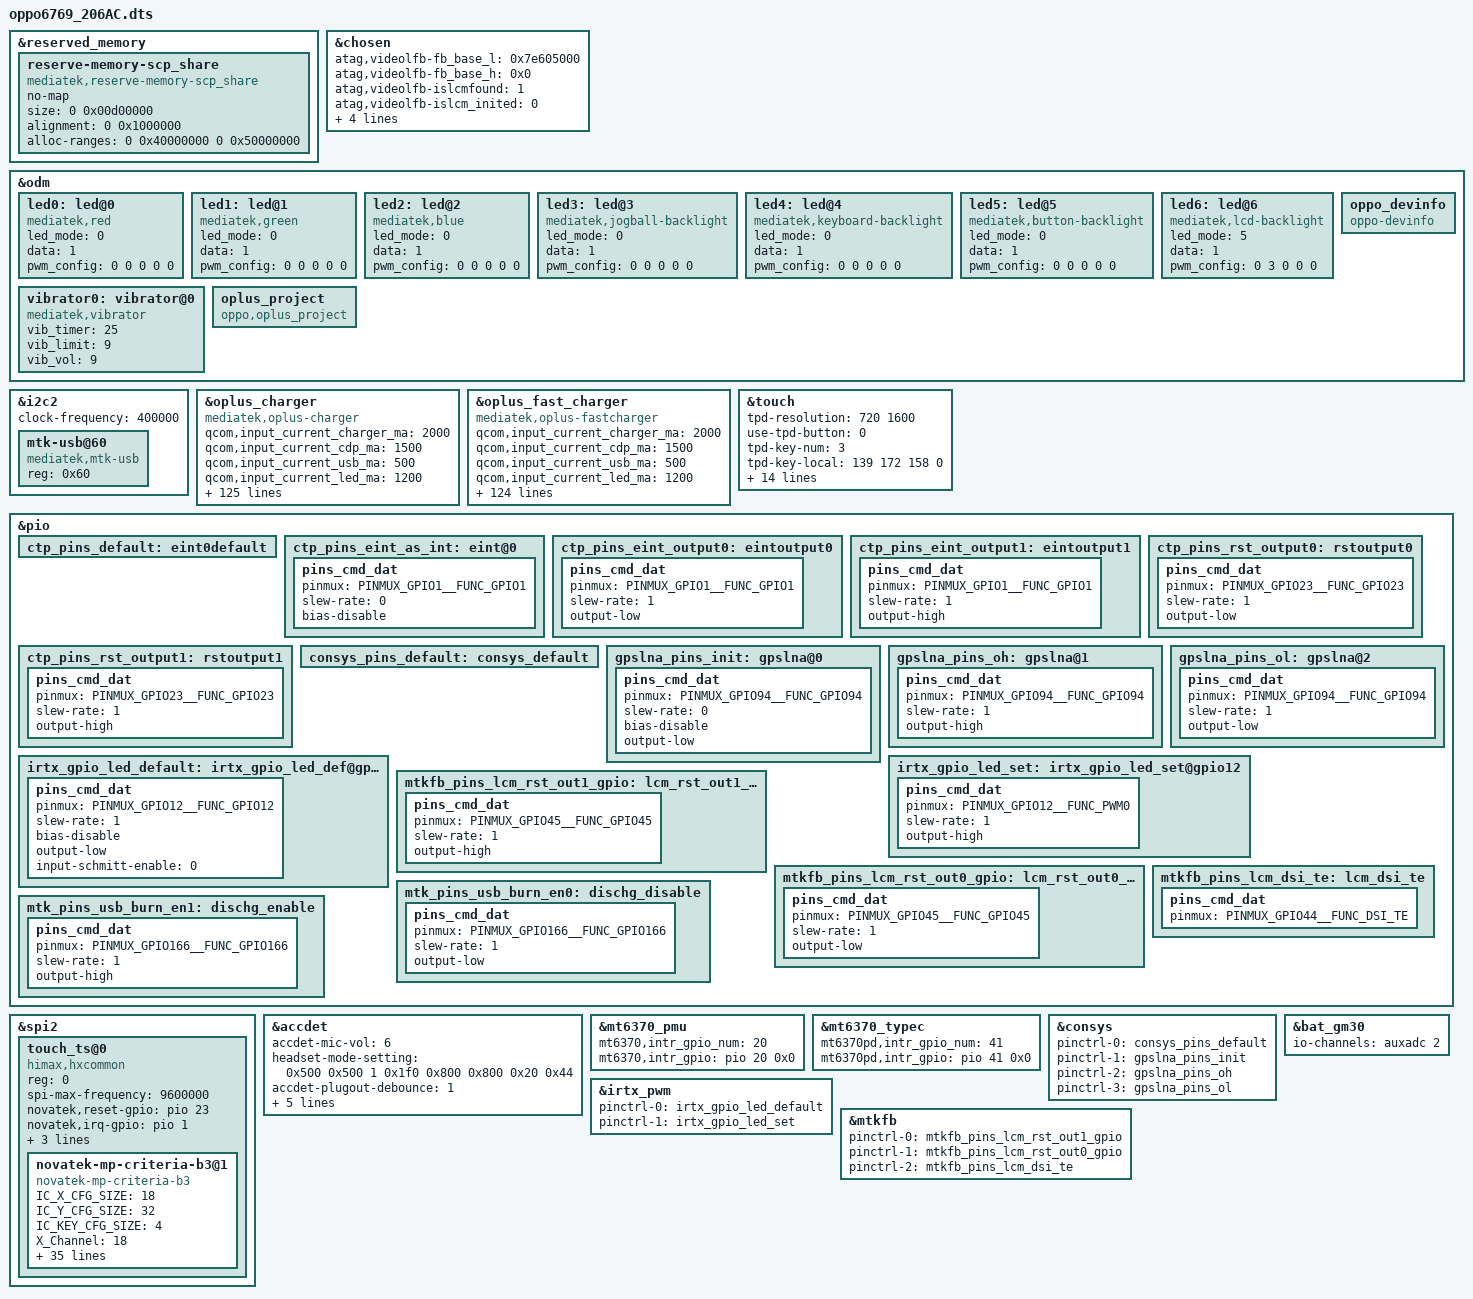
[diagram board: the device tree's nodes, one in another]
/*
 * Copyright (C) 2019 MediaTek Inc.
 *
 * This program is free software; you can redistribute it and/or modify
 * it under the terms of the GNU General Public License version 2 as
 * published by the Free Software Foundation.
 *
 * This program is distributed in the hope that it will be useful,
 * but WITHOUT ANY WARRANTY; without even the implied warranty of
 * MERCHANTABILITY or FITNESS FOR A PARTICULAR PURPOSE.
 * See http://www.gnu.org/licenses/gpl-2.0.html for more details.
 */

/dts-v1/;
/plugin/;
#include <dt-bindings/interrupt-controller/irq.h>
#include <dt-bindings/interrupt-controller/arm-gic.h>
#include <dt-bindings/pinctrl/mt6768-pinfunc.h>

&reserved_memory {
	reserve-memory-scp_share {
		compatible = "mediatek,reserve-memory-scp_share";
		no-map;
		size = <0 0x00d00000>;
		alignment = <0 0x1000000>;
		alloc-ranges = <0 0x40000000 0 0x50000000>;
	};
};

/* chosen */
&chosen {

	atag,videolfb-fb_base_l = <0x7e605000>;
	atag,videolfb-fb_base_h = <0x0>;
	atag,videolfb-islcmfound = <1>;
	atag,videolfb-islcm_inited = <0>;
	atag,videolfb-fps= <6000>;
	atag,videolfb-vramSize= <0x017e8000>;
	atag,videolfb-lcmname=
		"hx83112b_fhdp_dsi_cmd_auo_rt5081_drv";
};

&odm {
	led0:led@0 {
		compatible = "mediatek,red";
		led_mode = <0>;
		data = <1>;
		pwm_config = <0 0 0 0 0>;
	};
	led1:led@1 {
		compatible = "mediatek,green";
		led_mode = <0>;
		data = <1>;
		pwm_config = <0 0 0 0 0>;
	};
	led2:led@2 {
		compatible = "mediatek,blue";
		led_mode = <0>;
		data = <1>;
		pwm_config = <0 0 0 0 0>;
	};
	led3:led@3 {
		compatible = "mediatek,jogball-backlight";
		led_mode = <0>;
		data = <1>;
		pwm_config = <0 0 0 0 0>;
	};
	led4:led@4 {
		compatible = "mediatek,keyboard-backlight";
		led_mode = <0>;
		data = <1>;
		pwm_config = <0 0 0 0 0>;
	};
	led5:led@5 {
		compatible = "mediatek,button-backlight";
		led_mode = <0>;
		data = <1>;
		pwm_config = <0 0 0 0 0>;
	};
	led6:led@6 {
		compatible = "mediatek,lcd-backlight";
		led_mode = <5>;
		data = <1>;
		pwm_config = <0 3 0 0 0>;
	};
	vibrator0:vibrator@0 {
		compatible = "mediatek,vibrator";
		vib_timer = <25>;
		vib_limit = <9>;
		vib_vol= <9>;
	};
/*VNDOR_EDIT oppo project start */
	oplus_project:oplus_project {
		compatible = "oppo,oplus_project";
	};
	oppo_devinfo:oppo_devinfo {
		compatible = "oppo-devinfo";
	};
};

&i2c2 {
	clock-frequency = <400000>;

	mtk-usb@60 {
		compatible = "mediatek,mtk-usb";
		reg = <0x60>;
		status = "okay";
	};
};

//#ifdef ODM_WT_EDIT
&oplus_charger {
	compatible = "mediatek,oplus-charger";
	//pinctrl-names = "default", "charger_gpio_as_output_low", "charger_gpio_as_output_high", "ship_sleep", "ship_active", "shortc_active";
	//pinctrl-0 = <&charger_pins_default>;
	//pinctrl-1 = <&charger_pins_eint_output0>;
	//pinctrl-2 = <&charger_pins_eint_output1>;
	//pinctrl-3 = <&ship_sleep_gpio>;
	//pinctrl-4 = <&ship_active_gpio>;
	//pinctrl-5 = <&shortc_active_gpio>;

	//for oplus chg framework:
	qcom,input_current_charger_ma = <2000>;
	qcom,input_current_cdp_ma = <1500>;
	qcom,input_current_usb_ma = <500>;
	qcom,input_current_led_ma = <1200>;
	qcom,input_current_led_ma_forcmcc = <500>;
	qcom,input_current_camera_ma = <1200>;
	qcom,input_current_calling_ma = <1200>;
	
	qcom,input_current_led_ma_high = <1200>;
	qcom,input_current_led_ma_warm = <1500>;
	qcom,input_current_led_ma_normal = <2000>;

	qcom,led_high_bat_decidegc = <370>;
	qcom,led_warm_bat_decidegc = <350>;

	qcom,iterm_disabled = <0>;
	qcom,iterm_ma = <265>;
	qcom,recharge-mv = <115>;

	qcom,batt_capacity_mah = <5000>; /*typical capacity*/
	//qcom,batt_capacity_mah = <3900>; /*rated capacity*/

	qcom,removed_bat_decidegc = <190>;  /* < -19C */

	qcom,cold_bat_decidegc = <20>;  /* -2C ~ 0C */
	qcom,temp_cold_vfloat_mv = <3980>;
	qcom,temp_cold_fastchg_current_ma = <350>;

	qcom,little_cold_bat_decidegc = <0>;	/* 0C ~ 5C */
	qcom,temp_little_cold_vfloat_mv = <4435>;
	qcom,temp_little_cold_fastchg_current_ma_high = <650>;
	qcom,temp_little_cold_fastchg_current_ma_low = <650>;
	qcom,temp_little_cold_fastchg_current_ma = <650>;
	monet,temp_little_cold_usbchg_current_ma_high = <650>;
	monet,temp_little_cold_usbchg_current_ma_low = <650>;
	monet,temp_little_cold_usbchg_current_ma = <650>;

	qcom,cool_bat_decidegc = <50>;	/* 5C ~ 12C */
	qcom,temp_cool_vfloat_mv = <4435>;
	qcom,temp_cool_fastchg_current_ma_high = <1350>;
	qcom,temp_cool_fastchg_current_ma_low = <650>;
	monet,temp_cool_usbchg_current_ma_high = <650>;
	monet,temp_cool_usbchg_current_ma_low = <550>;

	qcom,little_cool_bat_decidegc = <120>;	/* 12C ~ 16C */
	qcom,temp_little_cool_vfloat_mv = <4435>;
	qcom,temp_little_cool_fastchg_current_ma = <2050>;
	monet,temp_little_cool_usbchg_current_ma = <550>;

	qcom,normal_bat_decidegc = <160>;	/* 16C ~ 45C */
	qcom,temp_normal_fastchg_current_ma = <2200>;
	monet,temp_normal_usbchg_current_ma = <550>;
	qcom,temp_normal_vfloat_mv = <4435>;

	qcom,warm_bat_decidegc = <440>;		/* 44C ~ 53C */ /*8pin Bat Vooc project need add 3 degree C*/
	qcom,temp_warm_vfloat_mv = <4130>;
	qcom,temp_warm_fastchg_current_ma = <1350>;
	monet,temp_warm_usbchg_current_ma = <550>;
	qcom,temp_warm_fastchg_current_ma_led_on = <500>;

	qcom,hot_bat_decidegc = <530>;  /* > 53C */

	qcom,non_standard_vfloat_mv = <3980>;
	qcom,non_standard_fastchg_current_ma = <512>;

	qcom,short_c_bat_cv_mv = <4330>;
	qcom,short_c_bat_vfloat_mv = <3800>;
	qcom,short_c_bat_fastchg_current_ma = <512>;
	qcom,short_c_bat_vfloat_sw_limit = <3750>;

	qcom,cold_vfloat_sw_limit = <3930>;
	qcom,little_cold_vfloat_sw_limit = <4380>;
	qcom,cool_vfloat_sw_limit = <4380>;
	qcom,little_cool_vfloat_sw_limit = <4380>;
	qcom,normal_vfloat_sw_limit = <4380>;
	qcom,warm_vfloat_sw_limit = <4080>;
	qcom,non_standard_vfloat_sw_limit = <3930>;

	qcom,max_chg_time_sec = <36000>;
	qcom,charger_hv_thr = <5800>;
	qcom,charger_recv_thr = <5800>;
	qcom,charger_lv_thr = <3400>;
	qcom,vbatt_full_thr = <4400>;
	qcom,vbatt_hv_thr = <4550>;

	qcom,vfloat_step_mv = <10>;
	qcom,non_standard_vfloat_over_sw_limit = <4000>;
	qcom,cold_vfloat_over_sw_limit = <4000>;
	qcom,little_cold_vfloat_over_sw_limit = <4450>;
	qcom,cool_vfloat_over_sw_limit = <4450>;
	qcom,little_cool_vfloat_over_sw_limit = <4450>;
	qcom,normal_vfloat_over_sw_limit = <4450>;
	qcom,warm_vfloat_over_sw_limit = <4150>;

	qcom,vbatt_power_off = <3300>;
	qcom,vbatt_soc_1 = <3410>;
	qcom,vooc_project = <0>;
	qcom,vbatt_num = <1>;

	qcom,normal_vterm_hw_inc = <150>;
	qcom,non_normal_vterm_hw_inc = <10>;

	qcom,ff1_normal_fastchg_ma = <1088>;
	qcom,ffc2_normal_fastchg_ma = <780>;/*16C~35c*/
	qcom,ffc2_temp_warm_decidegc = <350>;
	qcom,ffc2_warm_fastchg_ma = <840>;/*35C~40c*/
	qcom,ffc2_temp_high_decidegc = <400>;
	qcom,ffc2_temp_low_decidegc = <120>;
	qcom,ff1_exit_step_ma = <488>;
	qcom,ff1_warm_exit_step_ma = <418>;
	qcom,ffc2_exit_step_ma = <180>;
	qcom,ffc2_warm_exit_step_ma = <170>;

	qcom,ffc_normal_vfloat_sw_limit = <4430>;
	qcom,ffc_temp_normal_vfloat_mv = <4500>;
	qcom,ffc_normal_vfloat_over_sw_limit = <4500>;

	qcom,default_iterm_ma = <265>;
	qcom,default_temp_normal_fastchg_current_ma = <2200>;
	qcom,default_normal_vfloat_sw_limit = <4380>;
	qcom,default_temp_normal_vfloat_mv = <4435>;
	qcom,default_normal_vfloat_over_sw_limit = <4450>;

	//for 2nd chip:
	qcom,iterm_ma_2nd = <300>;
	qcom,recharge-mv_2nd = <121>;

	qcom,temp_little_cold_vfloat_mv_2nd = <4391>;	/* 0C ~ 5C */
	qcom,temp_cool_vfloat_mv_2nd = <4391>;	/* 5C ~ 12C */
	qcom,temp_little_cool_vfloat_mv_2nd = <4391>;	/* 12C ~ 16C */
	qcom,temp_normal_vfloat_mv_2nd = <4391>;	/* 16C ~ 45C */

	qcom,little_cold_vfloat_over_sw_limit_2nd = <4395>;
	qcom,cool_vfloat_over_sw_limit_2nd = <4395>;
	qcom,little_cool_vfloat_over_sw_limit_2nd = <4395>;
	qcom,normal_vfloat_over_sw_limit_2nd = <4395>;

	qcom,default_iterm_ma_2nd = <300>;
	qcom,default_temp_normal_vfloat_mv_2nd = <4391>;
	qcom,default_normal_vfloat_over_sw_limit_2nd = <4395>;

	//for control:
	//qcom,suspend_after_full;
	qcom,check_batt_full_by_sw;
	//qcom,external_gauge;
	qcom,chg_ctrl_by_calling;
	qcom,chg_ctrl_by_lcd;
	qcom,chg_ctrl_by_camera;
	qcom,sw_vfloat_over_protect_enable;
	//qcom,ffc_support;

	//GPIO config:
	//qcom,chargerid_switch-gpio = <&pio 97 0x00>;
	//qcom,ship-gpio = <&pio 155 0x00>;
	//qcom,shortc-gpio = <&pio 77 0x00>;

	io-channels = <&auxadc 3>, <&auxadc 4>;
	io-channel-names = "usbtemp-ch3", "usbtemp-ch4";

	qcom,dischg-gpio = <&pio 166 0x00>;
	pinctrl-names = "dischg_disable", "dischg_enable";
	pinctrl-0 = <&mtk_pins_usb_burn_en0>;
	pinctrl-1 = <&mtk_pins_usb_burn_en1>;
	status = "okay";
};

&oplus_fast_charger {
	compatible = "mediatek,oplus-fastcharger";
	//pinctrl-names = "default", "charger_gpio_as_output_low", "charger_gpio_as_output_high", "ship_sleep", "ship_active", "shortc_active";
	//pinctrl-0 = <&charger_pins_default>;
	//pinctrl-1 = <&charger_pins_eint_output0>;
	//pinctrl-2 = <&charger_pins_eint_output1>;
	//pinctrl-3 = <&ship_sleep_gpio>;
	//pinctrl-4 = <&ship_active_gpio>;
	//pinctrl-5 = <&shortc_active_gpio>;

	//for oplus chg framework:
	qcom,input_current_charger_ma = <2000>;
	qcom,input_current_cdp_ma = <1500>;
	qcom,input_current_usb_ma = <500>;
	qcom,input_current_led_ma = <1200>;
	qcom,input_current_led_ma_forcmcc = <500>;
	qcom,input_current_camera_ma = <1200>;
	qcom,input_current_calling_ma = <1200>;

	qcom,input_current_led_ma_high = <1000>;
	qcom,input_current_led_ma_warm = <1500>;
	qcom,input_current_led_ma_normal = <2000>;

	qcom,led_high_bat_decidegc = <370>;
	qcom,led_warm_bat_decidegc = <340>;

	qcom,iterm_disabled = <0>;
	qcom,iterm_ma = <300>;
	qcom,recharge-mv = <115>;

	qcom,batt_capacity_mah = <6000>; /*typical capacity*/
	//qcom,batt_capacity_mah = <3900>; /*rated capacity*/

	qcom,removed_bat_decidegc = <190>;  /* < -19C */

	qcom,cold_bat_decidegc = <20>;  /* -2C ~ 0C */
	qcom,temp_cold_vfloat_mv = <3980>;
	qcom,temp_cold_fastchg_current_ma = <350>;

	qcom,little_cold_bat_decidegc = <0>;	/* 0C ~ 5C */
	qcom,temp_little_cold_vfloat_mv = <4435>;
	qcom,temp_little_cold_fastchg_current_ma_high = <2000>;
	qcom,temp_little_cold_fastchg_current_ma_low = <1650>;
	qcom,temp_little_cold_fastchg_current_ma = <2000>;
	monet,temp_little_cold_usbchg_current_ma_high = <650>;
	monet,temp_little_cold_usbchg_current_ma_low = <650>;
	monet,temp_little_cold_usbchg_current_ma = <650>;

	qcom,cool_bat_decidegc = <50>;	/* 5C ~ 12C */
	qcom,temp_cool_vfloat_mv = <4435>;
	qcom,temp_cool_fastchg_current_ma_high = <2750>;
	qcom,temp_cool_fastchg_current_ma_low = <2750>;
	monet,temp_cool_usbchg_current_ma_high = <650>;
	monet,temp_cool_usbchg_current_ma_low = <550>;

	qcom,little_cool_bat_decidegc = <120>;	/* 12C ~ 16C */
	qcom,temp_little_cool_vfloat_mv = <4435>;
	qcom,temp_little_cool_fastchg_current_ma = <2750>;
	qcom,temp_little_cool_fastchg_current_ma_high = <3400>;
	monet,temp_little_cool_usbchg_current_ma = <550>;

	qcom,normal_bat_decidegc = <160>;	/* 16C ~ 45C */
	qcom,temp_normal_fastchg_current_ma = <2200>;
	monet,temp_normal_usbchg_current_ma = <550>;
	qcom,temp_normal_vfloat_mv = <4435>;

	qcom,warm_bat_decidegc = <450>;		/* 45C ~ 53C */ /*8pin Bat Vooc project need add 3 degree C*/
	qcom,temp_warm_vfloat_mv = <4130>;
	qcom,temp_warm_fastchg_current_ma = <1650>;
	monet,temp_warm_usbchg_current_ma = <550>;
	qcom,temp_warm_fastchg_current_ma_led_on = <500>;

	qcom,hot_bat_decidegc = <530>;  /* > 53C */

	qcom,non_standard_vfloat_mv = <3980>;
	qcom,non_standard_fastchg_current_ma = <512>;

	qcom,short_c_bat_cv_mv = <4330>;
	qcom,short_c_bat_vfloat_mv = <3800>;
	qcom,short_c_bat_fastchg_current_ma = <512>;
	qcom,short_c_bat_vfloat_sw_limit = <3750>;

	qcom,cold_vfloat_sw_limit = <3930>;
	qcom,little_cold_vfloat_sw_limit = <4380>;
	qcom,cool_vfloat_sw_limit = <4380>;
	qcom,little_cool_vfloat_sw_limit = <4380>;
	qcom,normal_vfloat_sw_limit = <4380>;
	qcom,warm_vfloat_sw_limit = <4080>;
	qcom,non_standard_vfloat_sw_limit = <3930>;

	qcom,max_chg_time_sec = <84384>;
	qcom,charger_hv_thr = <9800>;
	qcom,charger_recv_thr = <9800>;
	qcom,charger_lv_thr = <3400>;
	qcom,vbatt_full_thr = <4400>;
	qcom,vbatt_hv_thr = <4550>;

	qcom,vfloat_step_mv = <10>;
	qcom,non_standard_vfloat_over_sw_limit = <4000>;
	qcom,cold_vfloat_over_sw_limit = <4000>;
	qcom,little_cold_vfloat_over_sw_limit = <4450>;
	qcom,cool_vfloat_over_sw_limit = <4450>;
	qcom,little_cool_vfloat_over_sw_limit = <4450>;
	qcom,normal_vfloat_over_sw_limit = <4450>;
	qcom,warm_vfloat_over_sw_limit = <4150>;

	qcom,vbatt_power_off = <3300>;
	qcom,vbatt_soc_1 = <3410>;
	qcom,vooc_project = <0>;
	qcom,vbatt_num = <1>;

	qcom,normal_vterm_hw_inc = <150>;
	qcom,non_normal_vterm_hw_inc = <10>;

	qcom,ff1_normal_fastchg_ma = <1088>;
	qcom,ffc2_normal_fastchg_ma = <780>;/*16C~35c*/
	qcom,ffc2_temp_warm_decidegc = <350>;
	qcom,ffc2_warm_fastchg_ma = <840>;/*35C~40c*/
	qcom,ffc2_temp_high_decidegc = <400>;
	qcom,ffc2_temp_low_decidegc = <120>;
	qcom,ff1_exit_step_ma = <488>;
	qcom,ff1_warm_exit_step_ma = <418>;
	qcom,ffc2_exit_step_ma = <180>;
	qcom,ffc2_warm_exit_step_ma = <170>;

	qcom,ffc_normal_vfloat_sw_limit = <4430>;
	qcom,ffc_temp_normal_vfloat_mv = <4500>;
	qcom,ffc_normal_vfloat_over_sw_limit = <4500>;

	qcom,default_iterm_ma = <300>;
	qcom,default_temp_normal_fastchg_current_ma = <2200>;
	qcom,default_normal_vfloat_sw_limit = <4380>;
	qcom,default_temp_normal_vfloat_mv = <4435>;
	qcom,default_normal_vfloat_over_sw_limit = <4450>;

	//for 2nd chip:
	qcom,iterm_ma_2nd = <300>;
	qcom,recharge-mv_2nd = <121>;

	qcom,temp_little_cold_vfloat_mv_2nd = <4391>;	/* 0C ~ 5C */
	qcom,temp_cool_vfloat_mv_2nd = <4391>;	/* 5C ~ 12C */
	qcom,temp_little_cool_vfloat_mv_2nd = <4391>;	/* 12C ~ 16C */
	qcom,temp_normal_vfloat_mv_2nd = <4391>;	/* 16C ~ 45C */

	qcom,little_cold_vfloat_over_sw_limit_2nd = <4395>;
	qcom,cool_vfloat_over_sw_limit_2nd = <4395>;
	qcom,little_cool_vfloat_over_sw_limit_2nd = <4395>;
	qcom,normal_vfloat_over_sw_limit_2nd = <4395>;

	qcom,default_iterm_ma_2nd = <300>;
	qcom,default_temp_normal_vfloat_mv_2nd = <4391>;
	qcom,default_normal_vfloat_over_sw_limit_2nd = <4395>;

	//for control:
	//qcom,suspend_after_full;
	qcom,check_batt_full_by_sw;
	//qcom,external_gauge;
	qcom,chg_ctrl_by_calling;
	qcom,chg_ctrl_by_lcd;
	qcom,chg_ctrl_by_camera;
	qcom,sw_vfloat_over_protect_enable;
	//qcom,ffc_support;

	//GPIO config:
	//qcom,chargerid_switch-gpio = <&pio 97 0x00>;
	//qcom,ship-gpio = <&pio 155 0x00>;
	//qcom,shortc-gpio = <&pio 77 0x00>;

	qcom,vbatt_pdqc_to_5v_thr = <4420>;
	status = "okay";
};

/* TOUCH start */
&touch {
	tpd-resolution = <720 1600>;
	use-tpd-button = <0>;
	tpd-key-num = <3>;
	tpd-key-local= <139 172 158 0>;
	tpd-key-dim-local = <90 883 100 40 230
				883 100 40 370 883 100 40 0 0 0 0>;
	tpd-max-touch-num = <10>;
	tpd-filter-enable = <0>;
	tpd-filter-pixel-density = <168>;
	tpd-filter-custom-prameters = <0 0 0 0 0 0 0 0 0 0 0 0>;
	tpd-filter-custom-speed = <0 0 0>;
	pinctrl-names = "default", "state_eint_as_int",
		"state_eint_output0", "state_eint_output1",
		"state_rst_output0", "state_rst_output1";
	pinctrl-0 = <&ctp_pins_default>;
	pinctrl-1 = <&ctp_pins_eint_as_int>;
	pinctrl-2 = <&ctp_pins_eint_output0>;
	pinctrl-3 = <&ctp_pins_eint_output1>;
	pinctrl-4 = <&ctp_pins_rst_output0>;
	pinctrl-5 = <&ctp_pins_rst_output1>;
	status = "okay";
};
&pio {
	ctp_pins_default: eint0default {
	};
	ctp_pins_eint_as_int: eint@0 {
		pins_cmd_dat {
			pinmux = <PINMUX_GPIO1__FUNC_GPIO1>;
			slew-rate = <0>;
			bias-disable;
		};
	};
	ctp_pins_eint_output0: eintoutput0 {
		pins_cmd_dat {
			pinmux = <PINMUX_GPIO1__FUNC_GPIO1>;
			slew-rate = <1>;
			output-low;
		};
	};
	ctp_pins_eint_output1: eintoutput1 {
		pins_cmd_dat {
			pinmux = <PINMUX_GPIO1__FUNC_GPIO1>;
			slew-rate = <1>;
			output-high;
	};
	};
	ctp_pins_rst_output0: rstoutput0 {
		pins_cmd_dat {
			pinmux = <PINMUX_GPIO23__FUNC_GPIO23>;
			slew-rate = <1>;
			output-low;
		};
	};
	ctp_pins_rst_output1: rstoutput1 {
		pins_cmd_dat {
			pinmux = <PINMUX_GPIO23__FUNC_GPIO23>;
			slew-rate = <1>;
			output-high;
		};
	};
};
&spi2 {
	#address-cells = <1>;
	#size-cells = <0>;

	touch_ts@0 {
		reg = <0>;
		compatible = "himax,hxcommon","novatek,NVT-ts-spi";
		spi-max-frequency = <9600000>;
		status = "okay";

		novatek,reset-gpio = <&pio 23 0>;
		novatek,irq-gpio = <&pio 1 0>;
		novatek,reset_global_gpio = <&pio 45 0>;

		/* 672 */
		//novatek,swrst-n8-addr = <0x01F01A>;

		/* 672A, 525B */
		novatek,swrst-n8-addr = <0x03F0FE>;

		/* MP */
		novatek,mp-support-dt;

		novatek-mp-criteria-b3@1 {
			#address-cells = <1>;
			#size-cells = <0>;
			compatible = "novatek-mp-criteria-b3";

			/* MP Config */
			IC_X_CFG_SIZE = <18>;
			IC_Y_CFG_SIZE = <32>;
			IC_KEY_CFG_SIZE = <4>;
			X_Channel = <18>;
			Y_Channel = <32>;
			AIN_X = <0 1 2 3 4 5 6 7 8 9 10 11 12 13 14 15 16 17>;
			AIN_Y = <0 1 2 3 4 5 6 7 8 9 10 11 12 13 14 15 16 17 18 19
								20 21 22 23 24 25 26 27 28 29 30 31>;
			AIN_KEY = <0 1 2 0xFF>;

			/* MP Criteria */
			PS_Config_Lmt_Short_Rawdata_P = <
				14008 14008 14008 14008 14008 14008 14008 14008 14008 14008 14008 14008 14008 14008 14008 14008 14008 14008
				14008 14008 14008 14008 14008 14008 14008 14008 14008 14008 14008 14008 14008 14008 14008 14008 14008 14008
				14008 14008 14008 14008 14008 14008 14008 14008 14008 14008 14008 14008 14008 14008 14008 14008 14008 14008
				14008 14008 14008 14008 14008 14008 14008 14008 14008 14008 14008 14008 14008 14008 14008 14008 14008 14008
				14008 14008 14008 14008 14008 14008 14008 14008 14008 14008 14008 14008 14008 14008 14008 14008 14008 14008
				14008 14008 14008 14008 14008 14008 14008 14008 14008 14008 14008 14008 14008 14008 14008 14008 14008 14008
				14008 14008 14008 14008 14008 14008 14008 14008 14008 14008 14008 14008 14008 14008 14008 14008 14008 14008
				14008 14008 14008 14008 14008 14008 14008 14008 14008 14008 14008 14008 14008 14008 14008 14008 14008 14008
				14008 14008 14008 14008 14008 14008 14008 14008 14008 14008 14008 14008 14008 14008 14008 14008 14008 14008
				14008 14008 14008 14008 14008 14008 14008 14008 14008 14008 14008 14008 14008 14008 14008 14008 14008 14008
				14008 14008 14008 14008 14008 14008 14008 14008 14008 14008 14008 14008 14008 14008 14008 14008 14008 14008
				14008 14008 14008 14008 14008 14008 14008 14008 14008 14008 14008 14008 14008 14008 14008 14008 14008 14008
				14008 14008 14008 14008 14008 14008 14008 14008 14008 14008 14008 14008 14008 14008 14008 14008 14008 14008
				14008 14008 14008 14008 14008 14008 14008 14008 14008 14008 14008 14008 14008 14008 14008 14008 14008 14008
				14008 14008 14008 14008 14008 14008 14008 14008 14008 14008 14008 14008 14008 14008 14008 14008 14008 14008
				14008 14008 14008 14008 14008 14008 14008 14008 14008 14008 14008 14008 14008 14008 14008 14008 14008 14008
				14008 14008 14008 14008 14008 14008 14008 14008 14008 14008 14008 14008 14008 14008 14008 14008 14008 14008
				14008 14008 14008 14008 14008 14008 14008 14008 14008 14008 14008 14008 14008 14008 14008 14008 14008 14008
				14008 14008 14008 14008 14008 14008 14008 14008 14008 14008 14008 14008 14008 14008 14008 14008 14008 14008
				14008 14008 14008 14008 14008 14008 14008 14008 14008 14008 14008 14008 14008 14008 14008 14008 14008 14008
				14008 14008 14008 14008 14008 14008 14008 14008 14008 14008 14008 14008 14008 14008 14008 14008 14008 14008
				14008 14008 14008 14008 14008 14008 14008 14008 14008 14008 14008 14008 14008 14008 14008 14008 14008 14008
				14008 14008 14008 14008 14008 14008 14008 14008 14008 14008 14008 14008 14008 14008 14008 14008 14008 14008
				14008 14008 14008 14008 14008 14008 14008 14008 14008 14008 14008 14008 14008 14008 14008 14008 14008 14008
				14008 14008 14008 14008 14008 14008 14008 14008 14008 14008 14008 14008 14008 14008 14008 14008 14008 14008
				14008 14008 14008 14008 14008 14008 14008 14008 14008 14008 14008 14008 14008 14008 14008 14008 14008 14008
				14008 14008 14008 14008 14008 14008 14008 14008 14008 14008 14008 14008 14008 14008 14008 14008 14008 14008
				14008 14008 14008 14008 14008 14008 14008 14008 14008 14008 14008 14008 14008 14008 14008 14008 14008 14008
				14008 14008 14008 14008 14008 14008 14008 14008 14008 14008 14008 14008 14008 14008 14008 14008 14008 14008
				14008 14008 14008 14008 14008 14008 14008 14008 14008 14008 14008 14008 14008 14008 14008 14008 14008 14008
				14008 14008 14008 14008 14008 14008 14008 14008 14008 14008 14008 14008 14008 14008 14008 14008 14008 14008
				14008 14008 14008 14008 14008 14008 14008 14008 14008 14008 14008 14008 14008 14008 14008 14008 14008 14008
				>;

			PS_Config_Lmt_Short_Rawdata_N = <
				11376 11376 11376 11376 11376 11376 11376 11376 11376 11376 11376 11376 11376 11376 11376 11376 11376 11376
				11376 11376 11376 11376 11376 11376 11376 11376 11376 11376 11376 11376 11376 11376 11376 11376 11376 11376
				11376 11376 11376 11376 11376 11376 11376 11376 11376 11376 11376 11376 11376 11376 11376 11376 11376 11376
				11376 11376 11376 11376 11376 11376 11376 11376 11376 11376 11376 11376 11376 11376 11376 11376 11376 11376
				11376 11376 11376 11376 11376 11376 11376 11376 11376 11376 11376 11376 11376 11376 11376 11376 11376 11376
				11376 11376 11376 11376 11376 11376 11376 11376 11376 11376 11376 11376 11376 11376 11376 11376 11376 11376
				11376 11376 11376 11376 11376 11376 11376 11376 11376 11376 11376 11376 11376 11376 11376 11376 11376 11376
				11376 11376 11376 11376 11376 11376 11376 11376 11376 11376 11376 11376 11376 11376 11376 11376 11376 11376
				11376 11376 11376 11376 11376 11376 11376 11376 11376 11376 11376 11376 11376 11376 11376 11376 11376 11376
				11376 11376 11376 11376 11376 11376 11376 11376 11376 11376 11376 11376 11376 11376 11376 11376 11376 11376
				11376 11376 11376 11376 11376 11376 11376 11376 11376 11376 11376 11376 11376 11376 11376 11376 11376 11376
				11376 11376 11376 11376 11376 11376 11376 11376 11376 11376 11376 11376 11376 11376 11376 11376 11376 11376
				11376 11376 11376 11376 11376 11376 11376 11376 11376 11376 11376 11376 11376 11376 11376 11376 11376 11376
				11376 11376 11376 11376 11376 11376 11376 11376 11376 11376 11376 11376 11376 11376 11376 11376 11376 11376
				11376 11376 11376 11376 11376 11376 11376 11376 11376 11376 11376 11376 11376 11376 11376 11376 11376 11376
				11376 11376 11376 11376 11376 11376 11376 11376 11376 11376 11376 11376 11376 11376 11376 11376 11376 11376
				11376 11376 11376 11376 11376 11376 11376 11376 11376 11376 11376 11376 11376 11376 11376 11376 11376 11376
				11376 11376 11376 11376 11376 11376 11376 11376 11376 11376 11376 11376 11376 11376 11376 11376 11376 11376
				11376 11376 11376 11376 11376 11376 11376 11376 11376 11376 11376 11376 11376 11376 11376 11376 11376 11376
				11376 11376 11376 11376 11376 11376 11376 11376 11376 11376 11376 11376 11376 11376 11376 11376 11376 11376
				11376 11376 11376 11376 11376 11376 11376 11376 11376 11376 11376 11376 11376 11376 11376 11376 11376 11376
				11376 11376 11376 11376 11376 11376 11376 11376 11376 11376 11376 11376 11376 11376 11376 11376 11376 11376
				11376 11376 11376 11376 11376 11376 11376 11376 11376 11376 11376 11376 11376 11376 11376 11376 11376 11376
				11376 11376 11376 11376 11376 11376 11376 11376 11376 11376 11376 11376 11376 11376 11376 11376 11376 11376
				11376 11376 11376 11376 11376 11376 11376 11376 11376 11376 11376 11376 11376 11376 11376 11376 11376 11376
				11376 11376 11376 11376 11376 11376 11376 11376 11376 11376 11376 11376 11376 11376 11376 11376 11376 11376
				11376 11376 11376 11376 11376 11376 11376 11376 11376 11376 11376 11376 11376 11376 11376 11376 11376 11376
				11376 11376 11376 11376 11376 11376 11376 11376 11376 11376 11376 11376 11376 11376 11376 11376 11376 11376
				11376 11376 11376 11376 11376 11376 11376 11376 11376 11376 11376 11376 11376 11376 11376 11376 11376 11376
				11376 11376 11376 11376 11376 11376 11376 11376 11376 11376 11376 11376 11376 11376 11376 11376 11376 11376
				11376 11376 11376 11376 11376 11376 11376 11376 11376 11376 11376 11376 11376 11376 11376 11376 11376 11376
				11376 11376 11376 11376 11376 11376 11376 11376 11376 11376 11376 11376 11376 11376 11376 11376 11376 11376
				>;

			PS_Config_Lmt_Open_Rawdata_P = <
				3166 3178 3169 3189 3215 3180 3164 3236 65535 65535 3143 3071 3098 3136 3178 3232 3257 3200
				2934 2955 2987 3045 3096 3087 3070 3054 3001 2947 3018 3029 3056 3068 3087 3105 3084 3014
				3014 3035 3067 3133 3196 3187 3169 3155 3081 2966 3047 3067 3087 3101 3116 3138 3116 3061
				3031 3039 3073 3138 3204 3199 3179 3165 3089 3005 3091 3109 3130 3144 3161 3182 3166 3120
				3054 3066 3098 3166 3234 3224 3204 3189 3110 2996 3082 3103 3123 3140 3151 3173 3164 3119
				3052 3060 3094 3161 3232 3239 3220 3207 3120 3046 3141 3159 3182 3200 3214 3236 3234 3186
				3136 3162 3187 3190 3185 3172 3173 3157 3115 3238 3270 3295 3291 3283 3203 3120 3059 3001
				3175 3193 3225 3229 3220 3214 3203 3196 3151 3255 3290 3305 3316 3318 3243 3158 3096 3042
				3175 3194 3229 3238 3225 3222 3201 3194 3150 3269 3305 3319 3337 3336 3263 3175 3115 3060
				3224 3243 3287 3291 3284 3281 3264 3248 3200 3312 3351 3375 3390 3397 3318 3232 3171 3116
				3262 3278 3326 3329 3315 3308 3290 3271 3234 3318 3355 3376 3397 3406 3343 3260 3197 3144
				3302 3318 3371 3376 3364 3355 3325 3309 3273 3364 3403 3424 3456 3465 3403 3316 3252 3196
				3288 3301 3379 3381 3374 3360 3334 3320 3290 3382 3417 3435 3466 3479 3418 3340 3262 3200
				3336 3364 3431 3441 3421 3413 3388 3374 3341 3416 3453 3472 3501 3509 3466 3385 3308 3242
				3369 3395 3459 3465 3451 3430 3413 3402 3362 3428 3470 3490 3508 3533 3487 3416 3340 3276
				3402 3430 3491 3508 3483 3474 3449 3437 3395 3470 3516 3539 3563 3579 3547 3474 3397 3332
				3424 3449 3512 3518 3504 3493 3469 3455 3413 3474 3519 3543 3568 3585 3554 3495 3421 3360
				3466 3494 3550 3560 3544 3535 3511 3498 3451 3508 3556 3581 3605 3623 3596 3539 3467 3402
				3505 3522 3582 3579 3574 3565 3546 3525 3477 3522 3582 3603 3634 3644 3624 3572 3511 3441
				3547 3568 3623 3633 3620 3606 3586 3565 3515 3547 3606 3628 3658 3673 3665 3612 3550 3477
				3563 3575 3630 3645 3630 3620 3602 3581 3528 3553 3616 3637 3668 3682 3680 3624 3567 3502
				3598 3605 3661 3680 3663 3651 3631 3610 3556 3584 3649 3673 3701 3715 3722 3669 3609 3547
				3637 3649 3687 3739 3733 3722 3701 3683 3623 3602 3673 3694 3726 3739 3763 3738 3693 3630
				3661 3669 3703 3745 3746 3733 3715 3697 3635 3641 3714 3736 3766 3778 3799 3787 3740 3680
				3698 3703 3738 3777 3782 3771 3754 3735 3670 3627 3700 3725 3752 3766 3787 3781 3738 3686
				3712 3715 3746 3780 3788 3775 3760 3742 3675 3675 3749 3775 3799 3815 3833 3836 3795 3747
				3553 3763 3785 3823 3830 3822 3824 3809 3742 3700 3774 3796 3801 3817 3834 3837 3806 3543
				3550 3763 3789 3813 3824 3815 3816 3799 3732 3733 3810 3833 3838 3857 3875 3892 3864 3589
				3596 3816 3836 3862 3875 3865 3864 3850 3778 3718 3801 3819 3827 3844 3864 3880 3858 3579
				3588 3809 3830 3851 3866 3858 3858 3845 3773 3771 3854 3873 3882 3899 3918 3942 3920 3637
				3640 3871 3885 3900 3914 3904 3906 3892 3817 3750 3836 3852 3861 3878 3896 3924 3911 3627
				3729 3789 3882 3894 3907 3896 3900 3886 3812 3802 3892 3908 3914 3929 3949 3976 3882 3773
				>;

			PS_Config_Lmt_Open_Rawdata_N = <
				1357 1362 1358 1366 1378 1363 1356 1387 (-65535) (-65535) 1347 1316 1327 1344 1362 1385 1396 1371
				1257 1266 1280 1305 1327 1323 1315 1309 1286 1263 1293 1298 1309 1315 1323 1330 1321 1291
				1291 1300 1314 1342 1369 1366 1358 1352 1320 1271 1306 1314 1323 1329 1335 1345 1335 1312
				1299 1302 1317 1345 1373 1371 1362 1356 1324 1288 1324 1332 1341 1347 1354 1363 1357 1337
				1309 1314 1327 1357 1386 1381 1373 1366 1333 1284 1321 1330 1338 1345 1350 1360 1356 1336
				1308 1311 1326 1354 1385 1388 1380 1374 1337 1305 1346 1354 1363 1371 1377 1387 1386 1365
				1344 1355 1366 1367 1365 1359 1360 1353 1335 1387 1401 1412 1410 1407 1372 1337 1311 1286
				1360 1368 1382 1384 1380 1377 1372 1369 1350 1395 1410 1416 1421 1422 1390 1353 1327 1303
				1360 1369 1384 1387 1382 1381 1372 1369 1350 1401 1416 1422 1430 1429 1398 1360 1335 1311
				1381 1390 1408 1410 1407 1406 1399 1392 1371 1419 1436 1446 1453 1456 1422 1385 1359 1335
				1398 1405 1425 1426 1420 1417 1410 1402 1386 1422 1438 1447 1456 1459 1432 1397 1370 1347
				1415 1422 1444 1447 1441 1438 1425 1418 1402 1441 1458 1467 1481 1485 1458 1421 1393 1369
				1409 1414 1448 1449 1446 1440 1429 1423 1410 1449 1464 1472 1485 1491 1465 1431 1398 1371
				1429 1441 1470 1474 1466 1462 1452 1446 1432 1464 1480 1488 1500 1504 1485 1450 1417 1389
				1444 1455 1482 1485 1479 1470 1462 1458 1441 1469 1487 1495 1503 1514 1494 1464 1431 1404
				1458 1470 1496 1503 1492 1489 1478 1473 1455 1487 1507 1516 1527 1534 1520 1489 1456 1428
				1467 1478 1505 1507 1501 1497 1486 1480 1462 1489 1508 1518 1529 1536 1523 1498 1466 1440
				1485 1497 1521 1525 1519 1515 1504 1499 1479 1503 1524 1534 1545 1552 1541 1516 1486 1458
				1502 1509 1535 1534 1531 1528 1519 1510 1490 1509 1535 1544 1557 1561 1553 1531 1504 1474
				1520 1529 1552 1557 1551 1545 1537 1528 1506 1520 1545 1555 1567 1574 1570 1548 1521 1490
				1527 1532 1555 1562 1555 1551 1543 1534 1512 1522 1549 1558 1572 1578 1577 1553 1528 1501
				1542 1545 1569 1577 1570 1564 1556 1547 1524 1536 1564 1574 1586 1592 1595 1572 1546 1520
				1558 1564 1580 1602 1600 1595 1586 1578 1552 1543 1574 1583 1597 1602 1612 1602 1582 1555
				1569 1572 1587 1605 1605 1600 1592 1584 1558 1560 1591 1601 1614 1619 1628 1623 1603 1577
				1585 1587 1602 1618 1621 1616 1609 1600 1573 1554 1585 1596 1608 1614 1623 1620 1602 1579
				1591 1592 1605 1620 1623 1618 1611 1603 1575 1575 1606 1618 1628 1635 1642 1644 1626 1606
				1522 1612 1622 1638 1641 1638 1639 1632 1603 1585 1617 1627 1629 1636 1643 1644 1631 1518
				1521 1612 1624 1634 1639 1635 1635 1628 1599 1600 1633 1642 1645 1653 1660 1668 1656 1538
				1541 1635 1644 1655 1660 1656 1656 1650 1619 1593 1629 1636 1640 1647 1656 1663 1653 1534
				1537 1632 1641 1650 1657 1653 1653 1648 1617 1616 1651 1660 1663 1671 1679 1689 1680 1558
				1560 1659 1665 1671 1677 1673 1674 1668 1636 1607 1644 1651 1654 1662 1669 1681 1676 1554
				1598 1624 1663 1669 1674 1669 1671 1665 1633 1629 1668 1675 1677 1684 1692 1704 1663 1617
				>;

			PS_Config_Lmt_FW_Rawdata_P = <
				2238 2237 2234 2245 2235 2240 2238 2237 65535 65535 2233 2254 2244 2234 2242 2240 2237 2234
				2247 2234 2245 2248 2244 2237 2245 2235 2231 2245 2249 2245 2249 2247 2235 2242 2249 2242
				2238 2234 2244 2249 2228 2237 2241 2233 2244 2252 2249 2249 2251 2244 2244 2259 2252 2242
				2247 2233 2234 2230 2224 2241 2235 2238 2240 2247 2237 2234 2234 2244 2234 2237 2252 2230
				2248 2235 2237 2237 2235 2242 2241 2244 2249 2247 2228 2231 2234 2255 2242 2235 2242 2244
				2231 2241 2244 2240 2226 2230 2228 2228 2247 2240 2240 2237 2237 2241 2238 2234 2233 2241
				2227 2242 2231 2231 2245 2238 2238 2228 2252 2224 2228 2244 2235 2244 2244 2237 2233 2238
				2244 2249 2233 2231 2240 2238 2235 2241 2252 2248 2247 2252 2254 2238 2238 2233 2230 2237
				2231 2254 2237 2240 2233 2237 2234 2235 2248 2244 2241 2231 2233 2234 2248 2248 2245 2234
				2247 2226 2244 2248 2252 2252 2254 2259 2241 2244 2242 2240 2245 2247 2227 2237 2233 2230
				2231 2245 2247 2244 2241 2234 2237 2247 2234 2238 2235 2241 2235 2247 2230 2237 2254 2230
				2233 2230 2248 2233 2240 2235 2247 2254 2238 2240 2242 2237 2237 2254 2256 2241 2226 2244
				2238 2235 2245 2240 2233 2230 2231 2237 2235 2245 2238 2242 2235 2235 2227 2238 2233 2242
				2240 2242 2235 2251 2235 2231 2241 2248 2245 2234 2235 2234 2244 2231 2228 2240 2234 2249
				2226 2247 2237 2247 2237 2247 2237 2245 2238 2241 2244 2248 2254 2237 2230 2226 2235 2238
				2238 2248 2247 2248 2244 2241 2252 2247 2224 2244 2241 2241 2240 2244 2244 2241 2238 2231
				2244 2240 2240 2240 2238 2244 2234 2247 2234 2245 2245 2248 2252 2247 2240 2238 2235 2227
				2233 2235 2233 2228 2241 2251 2240 2230 2234 2247 2238 2244 2244 2234 2241 2240 2231 2238
				2258 2244 2242 2252 2245 2252 2249 2259 2241 2251 2249 2249 2248 2254 2248 2231 2241 2235
				2244 2251 2238 2241 2242 2237 2240 2240 2241 2238 2237 2234 2240 2251 2254 2245 2251 2247
				2231 2241 2228 2245 2228 2224 2223 2231 2240 2252 2234 2234 2234 2247 2248 2238 2237 2237
				2249 2254 2245 2242 2241 2248 2244 2237 2247 2242 2237 2233 2235 2241 2241 2238 2238 2241
				2249 2247 2244 2238 2245 2227 2234 2247 2234 2235 2238 2237 2241 2219 2220 2221 2241 2234
				2242 2258 2255 2249 2249 2240 2249 2252 2255 2249 2245 2245 2248 2241 2241 2245 2256 2247
				2235 2242 2234 2230 2242 2245 2247 2224 2231 2248 2237 2245 2247 2241 2245 2244 2247 2241
				2249 2251 2244 2241 2247 2240 2247 2242 2235 2245 2231 2233 2241 2228 2228 2230 2248 2252
				2235 2242 2242 2242 2240 2240 2245 2235 2233 2238 2234 2235 2238 2231 2233 2238 2245 2242
				2252 2241 2220 2231 2245 2249 2245 2228 2234 2237 2223 2221 2224 2242 2244 2238 2221 2230
				2241 2248 2235 2235 2235 2242 2241 2235 2238 2240 2245 2235 2235 2248 2256 2255 2252 2240
				2248 2247 2249 2259 2248 2242 2256 2262 2244 2241 2254 2248 2248 2249 2234 2235 2240 2234
				2224 2234 2240 2240 2249 2252 2252 2238 2238 2235 2244 2238 2238 2254 2255 2251 2242 2227
				2251 2228 2238 2245 2233 2245 2237 2233 2244 2249 2244 2240 2247 2237 2247 2241 2240 2254
				>;

			PS_Config_Lmt_FW_Rawdata_N = <
				959 958 957 962 958 960 959 958 (-65535) (-65535) 957 966 961 957 961 960 958 957
				963 957 962 963 961 958 962 958 956 962 964 962 964 963 958 961 964 961
				959 957 961 964 955 958 960 957 961 965 964 964 964 961 961 968 965 961
				963 957 957 955 953 960 958 959 960 963 958 957 957 961 957 958 965 955
				963 958 958 958 958 961 960 961 964 963 955 956 957 966 961 958 961 961
				956 960 961 960 954 955 955 955 963 960 960 958 958 960 959 957 957 960
				954 961 956 956 962 959 959 955 965 953 955 961 958 961 961 958 957 959
				961 964 957 956 960 959 958 960 965 963 963 965 966 959 959 957 955 958
				956 966 958 960 957 958 957 958 963 961 960 956 957 957 963 963 962 957
				963 954 961 963 965 965 966 968 960 961 961 960 962 963 954 958 957 955
				956 962 963 961 960 957 958 963 957 959 958 960 958 963 955 958 966 955
				957 955 963 957 960 958 963 966 959 960 961 958 958 966 967 960 954 961
				959 958 962 960 957 955 956 958 958 962 959 961 958 958 954 959 957 961
				960 961 958 964 958 956 960 963 962 957 958 957 961 956 955 960 957 964
				954 963 958 963 958 963 958 962 959 960 961 963 966 958 955 954 958 959
				959 963 963 963 961 960 965 963 953 961 960 960 960 961 961 960 959 956
				961 960 960 960 959 961 957 963 957 962 962 963 965 963 960 959 958 954
				957 958 957 955 960 964 960 955 957 963 959 961 961 957 960 960 956 959
				967 961 961 965 962 965 964 968 960 964 964 964 963 966 963 956 960 958
				961 964 959 960 961 958 960 960 960 959 958 957 960 964 966 962 964 963
				956 960 955 962 955 953 952 956 960 965 957 957 957 963 963 959 958 958
				964 966 962 961 960 963 961 958 963 961 958 957 958 960 960 959 959 960
				964 963 961 959 962 954 957 963 957 958 959 958 960 951 951 952 960 957
				961 967 966 964 964 960 964 965 966 964 962 962 963 960 960 962 967 963
				958 961 957 955 961 962 963 953 956 963 958 962 963 960 962 961 963 960
				964 964 961 960 963 960 963 961 958 962 956 957 960 955 955 955 963 965
				958 961 961 961 960 960 962 958 957 959 957 958 959 956 957 959 962 961
				965 960 951 956 962 964 962 955 957 958 952 952 953 961 961 959 952 955
				960 963 958 958 958 961 960 958 959 960 962 958 958 963 967 966 965 960
				963 963 964 968 963 961 967 969 961 960 966 963 963 964 957 958 960 957
				953 957 960 960 964 965 965 959 959 958 961 959 959 966 966 964 961 954
				964 955 959 962 957 962 958 957 961 964 961 960 963 958 963 960 960 966
				>;

			PS_Config_Lmt_FW_CC_P = <
				97 97 97 97 97 97 99 99 65535 65535 100 100 99 99 99 99 99 99
				100 97 97 97 97 97 97 97 100 104 102 102 102 102 102 102 103 104
				102 99 99 99 99 99 99 99 103 104 102 102 102 100 100 102 102 104
				100 99 99 99 99 99 99 99 103 107 103 103 103 103 103 103 104 106
				102 100 100 100 100 100 100 100 104 104 102 102 102 102 102 102 102 104
				102 100 99 100 100 100 100 100 104 109 104 104 104 104 104 104 106 107
				104 102 102 102 102 100 102 102 104 107 104 104 104 104 103 103 103 106
				106 103 103 103 103 103 103 103 106 110 107 107 107 106 106 106 106 107
				104 102 102 102 102 102 102 102 104 107 104 104 104 104 103 103 103 106
				106 103 103 103 103 103 103 103 106 111 109 109 109 107 107 106 107 109
				104 102 102 102 100 100 100 100 104 109 104 104 104 104 104 103 103 106
				106 104 103 104 103 103 103 103 107 110 107 107 107 107 107 106 106 109
				104 102 102 102 102 102 102 102 104 109 106 106 106 104 104 103 104 106
				106 104 103 104 103 103 103 104 107 111 109 109 109 107 107 107 107 110
				103 102 102 102 100 100 102 102 104 109 106 106 106 104 104 104 104 107
				106 104 104 104 103 103 103 104 107 111 107 107 107 107 107 106 107 109
				104 103 103 103 103 102 103 103 106 109 106 106 106 104 104 104 104 107
				107 104 104 104 104 104 104 104 107 111 109 109 109 107 107 107 107 110
				104 102 102 102 102 102 102 102 106 109 106 106 106 106 106 104 106 107
				107 104 104 104 104 104 104 104 107 111 109 109 109 107 107 107 107 110
				106 103 103 103 103 103 103 103 106 109 106 106 106 106 106 106 106 109
				107 106 104 106 104 104 104 104 109 111 109 109 109 109 109 107 109 111
				104 103 102 103 102 102 102 102 106 107 104 104 104 104 104 104 104 107
				104 102 102 102 102 102 102 102 104 109 106 106 106 106 106 106 106 109
				106 103 103 103 103 102 103 103 106 107 104 104 104 104 104 104 104 107
				104 102 102 102 102 102 102 102 104 110 106 106 106 106 106 106 107 110
				103 103 103 103 103 102 103 103 106 107 104 104 104 104 104 104 104 106
				103 102 102 102 102 102 102 102 104 110 107 107 107 106 107 107 107 107
				103 103 102 102 102 102 102 102 106 107 104 104 104 104 104 104 104 104
				103 102 102 102 102 102 102 102 104 110 106 106 106 106 106 106 106 107
				103 103 102 102 102 102 102 102 106 109 104 104 104 104 104 104 104 106
				102 102 100 102 100 100 102 102 104 110 106 106 106 106 106 106 106 107
				>;

			PS_Config_Lmt_FW_CC_N = <
				44 44 44 44 44 44 44 44 (-65535) (-65535) 45 45 44 44 44 44 44 44
				45 44 44 44 44 44 44 44 45 47 45 45 45 45 45 45 46 47
				45 44 44 44 44 44 44 44 46 47 45 45 45 45 45 45 45 47
				45 44 44 44 44 44 44 44 46 48 46 46 46 46 46 46 47 47
				45 45 45 45 45 45 45 45 47 47 45 45 45 45 45 45 45 47
				45 45 44 45 45 45 45 45 47 48 47 47 47 47 47 47 47 48
				47 45 45 45 45 45 45 45 47 48 47 47 47 47 46 46 46 47
				47 46 46 46 46 46 46 46 47 49 48 48 48 47 47 47 47 48
				47 45 45 45 45 45 45 45 47 48 47 47 47 47 46 46 46 47
				47 46 46 46 46 46 46 46 47 50 48 48 48 48 48 47 48 48
				47 45 45 45 45 45 45 45 47 48 47 47 47 47 47 46 46 47
				47 47 46 47 46 46 46 46 48 49 48 48 48 48 48 47 47 48
				47 45 45 45 45 45 45 45 47 48 47 47 47 47 47 46 47 47
				47 47 46 47 46 46 46 47 48 50 48 48 48 48 48 48 48 49
				46 45 45 45 45 45 45 45 47 48 47 47 47 47 47 47 47 48
				47 47 47 47 46 46 46 47 48 50 48 48 48 48 48 47 48 48
				47 46 46 46 46 45 46 46 47 48 47 47 47 47 47 47 47 48
				48 47 47 47 47 47 47 47 48 50 48 48 48 48 48 48 48 49
				47 45 45 45 45 45 45 45 47 48 47 47 47 47 47 47 47 48
				48 47 47 47 47 47 47 47 48 50 48 48 48 48 48 48 48 49
				47 46 46 46 46 46 46 46 47 48 47 47 47 47 47 47 47 48
				48 47 47 47 47 47 47 47 48 50 48 48 48 48 48 48 48 50
				47 46 45 46 45 45 45 45 47 48 47 47 47 47 47 47 47 48
				47 45 45 45 45 45 45 45 47 48 47 47 47 47 47 47 47 48
				47 46 46 46 46 45 46 46 47 48 47 47 47 47 47 47 47 48
				47 45 45 45 45 45 45 45 47 49 47 47 47 47 47 47 48 49
				46 46 46 46 46 45 46 46 47 48 47 47 47 47 47 47 47 47
				46 45 45 45 45 45 45 45 47 49 48 48 48 47 48 48 48 48
				46 46 45 45 45 45 45 45 47 48 47 47 47 47 47 47 47 47
				46 45 45 45 45 45 45 45 47 49 47 47 47 47 47 47 47 48
				46 46 45 45 45 45 45 45 47 48 47 47 47 47 47 47 47 47
				45 45 45 45 45 45 45 45 47 49 47 47 47 47 47 47 47 48
				>;

			PS_Config_Lmt_FW_Diff_P = <
				50 50 50 50 50 50 50 50 65535 65535 50 50 50 50 50 50 50 50
				50 50 50 50 50 50 50 50 50 50 50 50 50 50 50 50 50 50
				50 50 50 50 50 50 50 50 50 50 50 50 50 50 50 50 50 50
				50 50 50 50 50 50 50 50 50 50 50 50 50 50 50 50 50 50
				50 50 50 50 50 50 50 50 50 50 50 50 50 50 50 50 50 50
				50 50 50 50 50 50 50 50 50 50 50 50 50 50 50 50 50 50
				50 50 50 50 50 50 50 50 50 50 50 50 50 50 50 50 50 50
				50 50 50 50 50 50 50 50 50 50 50 50 50 50 50 50 50 50
				50 50 50 50 50 50 50 50 50 50 50 50 50 50 50 50 50 50
				50 50 50 50 50 50 50 50 50 50 50 50 50 50 50 50 50 50
				50 50 50 50 50 50 50 50 50 50 50 50 50 50 50 50 50 50
				50 50 50 50 50 50 50 50 50 50 50 50 50 50 50 50 50 50
				50 50 50 50 50 50 50 50 50 50 50 50 50 50 50 50 50 50
				50 50 50 50 50 50 50 50 50 50 50 50 50 50 50 50 50 50
				50 50 50 50 50 50 50 50 50 50 50 50 50 50 50 50 50 50
				50 50 50 50 50 50 50 50 50 50 50 50 50 50 50 50 50 50
				50 50 50 50 50 50 50 50 50 50 50 50 50 50 50 50 50 50
				50 50 50 50 50 50 50 50 50 50 50 50 50 50 50 50 50 50
				50 50 50 50 50 50 50 50 50 50 50 50 50 50 50 50 50 50
				50 50 50 50 50 50 50 50 50 50 50 50 50 50 50 50 50 50
				50 50 50 50 50 50 50 50 50 50 50 50 50 50 50 50 50 50
				50 50 50 50 50 50 50 50 50 50 50 50 50 50 50 50 50 50
				50 50 50 50 50 50 50 50 50 50 50 50 50 50 50 50 50 50
				50 50 50 50 50 50 50 50 50 50 50 50 50 50 50 50 50 50
				50 50 50 50 50 50 50 50 50 50 50 50 50 50 50 50 50 50
				50 50 50 50 50 50 50 50 50 50 50 50 50 50 50 50 50 50
				50 50 50 50 50 50 50 50 50 50 50 50 50 50 50 50 50 50
				50 50 50 50 50 50 50 50 50 50 50 50 50 50 50 50 50 50
				50 50 50 50 50 50 50 50 50 50 50 50 50 50 50 50 50 50
				50 50 50 50 50 50 50 50 50 50 50 50 50 50 50 50 50 50
				50 50 50 50 50 50 50 50 50 50 50 50 50 50 50 50 50 50
				50 50 50 50 50 50 50 50 50 50 50 50 50 50 50 50 50 50
				>;

			PS_Config_Lmt_FW_Diff_N = <
				(-50) (-50) (-50) (-50) (-50) (-50) (-50) (-50) (-65535) (-65535) (-50) (-50) (-50) (-50) (-50) (-50) (-50) (-50)
				(-50) (-50) (-50) (-50) (-50) (-50) (-50) (-50) (-50) (-50) (-50) (-50) (-50) (-50) (-50) (-50) (-50) (-50)
				(-50) (-50) (-50) (-50) (-50) (-50) (-50) (-50) (-50) (-50) (-50) (-50) (-50) (-50) (-50) (-50) (-50) (-50)
				(-50) (-50) (-50) (-50) (-50) (-50) (-50) (-50) (-50) (-50) (-50) (-50) (-50) (-50) (-50) (-50) (-50) (-50)
				(-50) (-50) (-50) (-50) (-50) (-50) (-50) (-50) (-50) (-50) (-50) (-50) (-50) (-50) (-50) (-50) (-50) (-50)
				(-50) (-50) (-50) (-50) (-50) (-50) (-50) (-50) (-50) (-50) (-50) (-50) (-50) (-50) (-50) (-50) (-50) (-50)
				(-50) (-50) (-50) (-50) (-50) (-50) (-50) (-50) (-50) (-50) (-50) (-50) (-50) (-50) (-50) (-50) (-50) (-50)
				(-50) (-50) (-50) (-50) (-50) (-50) (-50) (-50) (-50) (-50) (-50) (-50) (-50) (-50) (-50) (-50) (-50) (-50)
				(-50) (-50) (-50) (-50) (-50) (-50) (-50) (-50) (-50) (-50) (-50) (-50) (-50) (-50) (-50) (-50) (-50) (-50)
				(-50) (-50) (-50) (-50) (-50) (-50) (-50) (-50) (-50) (-50) (-50) (-50) (-50) (-50) (-50) (-50) (-50) (-50)
				(-50) (-50) (-50) (-50) (-50) (-50) (-50) (-50) (-50) (-50) (-50) (-50) (-50) (-50) (-50) (-50) (-50) (-50)
				(-50) (-50) (-50) (-50) (-50) (-50) (-50) (-50) (-50) (-50) (-50) (-50) (-50) (-50) (-50) (-50) (-50) (-50)
				(-50) (-50) (-50) (-50) (-50) (-50) (-50) (-50) (-50) (-50) (-50) (-50) (-50) (-50) (-50) (-50) (-50) (-50)
				(-50) (-50) (-50) (-50) (-50) (-50) (-50) (-50) (-50) (-50) (-50) (-50) (-50) (-50) (-50) (-50) (-50) (-50)
				(-50) (-50) (-50) (-50) (-50) (-50) (-50) (-50) (-50) (-50) (-50) (-50) (-50) (-50) (-50) (-50) (-50) (-50)
				(-50) (-50) (-50) (-50) (-50) (-50) (-50) (-50) (-50) (-50) (-50) (-50) (-50) (-50) (-50) (-50) (-50) (-50)
				(-50) (-50) (-50) (-50) (-50) (-50) (-50) (-50) (-50) (-50) (-50) (-50) (-50) (-50) (-50) (-50) (-50) (-50)
				(-50) (-50) (-50) (-50) (-50) (-50) (-50) (-50) (-50) (-50) (-50) (-50) (-50) (-50) (-50) (-50) (-50) (-50)
				(-50) (-50) (-50) (-50) (-50) (-50) (-50) (-50) (-50) (-50) (-50) (-50) (-50) (-50) (-50) (-50) (-50) (-50)
				(-50) (-50) (-50) (-50) (-50) (-50) (-50) (-50) (-50) (-50) (-50) (-50) (-50) (-50) (-50) (-50) (-50) (-50)
				(-50) (-50) (-50) (-50) (-50) (-50) (-50) (-50) (-50) (-50) (-50) (-50) (-50) (-50) (-50) (-50) (-50) (-50)
				(-50) (-50) (-50) (-50) (-50) (-50) (-50) (-50) (-50) (-50) (-50) (-50) (-50) (-50) (-50) (-50) (-50) (-50)
				(-50) (-50) (-50) (-50) (-50) (-50) (-50) (-50) (-50) (-50) (-50) (-50) (-50) (-50) (-50) (-50) (-50) (-50)
				(-50) (-50) (-50) (-50) (-50) (-50) (-50) (-50) (-50) (-50) (-50) (-50) (-50) (-50) (-50) (-50) (-50) (-50)
				(-50) (-50) (-50) (-50) (-50) (-50) (-50) (-50) (-50) (-50) (-50) (-50) (-50) (-50) (-50) (-50) (-50) (-50)
				(-50) (-50) (-50) (-50) (-50) (-50) (-50) (-50) (-50) (-50) (-50) (-50) (-50) (-50) (-50) (-50) (-50) (-50)
				(-50) (-50) (-50) (-50) (-50) (-50) (-50) (-50) (-50) (-50) (-50) (-50) (-50) (-50) (-50) (-50) (-50) (-50)
				(-50) (-50) (-50) (-50) (-50) (-50) (-50) (-50) (-50) (-50) (-50) (-50) (-50) (-50) (-50) (-50) (-50) (-50)
				(-50) (-50) (-50) (-50) (-50) (-50) (-50) (-50) (-50) (-50) (-50) (-50) (-50) (-50) (-50) (-50) (-50) (-50)
				(-50) (-50) (-50) (-50) (-50) (-50) (-50) (-50) (-50) (-50) (-50) (-50) (-50) (-50) (-50) (-50) (-50) (-50)
				(-50) (-50) (-50) (-50) (-50) (-50) (-50) (-50) (-50) (-50) (-50) (-50) (-50) (-50) (-50) (-50) (-50) (-50)
				(-50) (-50) (-50) (-50) (-50) (-50) (-50) (-50) (-50) (-50) (-50) (-50) (-50) (-50) (-50) (-50) (-50) (-50)
				>;

			PS_Config_Diff_Test_Frame = <50>;

			PS_Config_Lmt_LPWG_Rawdata_P = <
				2251 2230 2238 2240 2244 2234 2237 2235 65535 65535 2240 2249 2247 2240 2247 2251 2252 2244
				2244 2247 2241 2233 2228 2245 2237 2244 2247 2249 2240 2244 2242 2240 2245 2244 2247 2240
				2237 2237 2248 2237 2245 2237 2231 2235 2240 2248 2241 2241 2242 2231 2235 2241 2252 2234
				2241 2226 2242 2245 2227 2238 2237 2235 2228 2231 2238 2241 2233 2231 2238 2233 2242 2233
				2238 2228 2237 2237 2235 2241 2235 2237 2249 2237 2247 2248 2247 2256 2249 2241 2240 2241
				2241 2242 2238 2241 2244 2241 2241 2235 2245 2228 2241 2237 2233 2245 2242 2240 2237 2237
				2252 2255 2238 2234 2249 2244 2244 2238 2233 2235 2248 2245 2251 2241 2233 2242 2233 2247
				2249 2230 2248 2242 2231 2233 2234 2234 2241 2247 2258 2254 2251 2251 2231 2224 2228 2245
				2237 2245 2230 2242 2237 2237 2238 2237 2238 2238 2238 2233 2231 2252 2256 2240 2249 2227
				2241 2245 2248 2249 2251 2242 2249 2255 2242 2251 2240 2238 2240 2228 2226 2240 2234 2238
				2248 2231 2235 2240 2244 2248 2238 2242 2247 2244 2251 2249 2255 2226 2240 2245 2240 2241
				2242 2247 2240 2248 2237 2237 2233 2242 2241 2238 2233 2231 2234 2249 2245 2235 2240 2240
				2242 2237 2230 2244 2244 2248 2237 2227 2233 2244 2244 2234 2238 2224 2234 2240 2237 2241
				2244 2233 2238 2240 2240 2237 2234 2240 2251 2247 2244 2244 2244 2226 2244 2245 2247 2237
				2238 2237 2238 2242 2240 2247 2251 2254 2245 2230 2248 2242 2241 2230 2233 2241 2228 2230
				2242 2245 2235 2247 2234 2237 2238 2258 2242 2247 2248 2247 2248 2244 2237 2245 2241 2217
				2261 2245 2255 2242 2245 2238 2241 2238 2234 2252 2242 2244 2240 2241 2240 2231 2241 2231
				2242 2234 2240 2241 2248 2249 2241 2247 2249 2237 2247 2244 2245 2238 2223 2247 2237 2258
				2240 2252 2259 2255 2256 2255 2258 2252 2245 2240 2245 2238 2238 2242 2238 2240 2237 2234
				2235 2252 2228 2251 2224 2228 2226 2238 2244 2237 2245 2255 2247 2244 2245 2245 2242 2235
				2241 2245 2226 2231 2224 2233 2224 2220 2231 2247 2244 2240 2240 2234 2247 2244 2249 2237
				2244 2244 2248 2244 2245 2240 2244 2252 2244 2230 2238 2237 2244 2240 2251 2240 2241 2235
				2248 2247 2230 2241 2240 2241 2234 2244 2235 2234 2226 2227 2220 2240 2219 2240 2245 2231
				2240 2252 2245 2244 2247 2247 2244 2261 2240 2251 2242 2237 2240 2233 2238 2241 2249 2245
				2242 2230 2241 2234 2245 2261 2256 2242 2226 2251 2241 2235 2244 2241 2248 2251 2249 2247
				2241 2244 2241 2238 2248 2247 2247 2248 2234 2247 2237 2233 2233 2226 2227 2221 2254 2249
				2240 2240 2247 2245 2248 2244 2254 2242 2249 2234 2241 2240 2235 2242 2242 2237 2252 2252
				2240 2240 2233 2240 2247 2251 2252 2247 2234 2238 2240 2233 2230 2251 2244 2240 2231 2238
				2255 2242 2244 2242 2238 2234 2244 2245 2233 2241 2248 2241 2240 2251 2251 2262 2247 2255
				2248 2252 2244 2248 2252 2241 2252 2259 2252 2237 2249 2247 2244 2245 2247 2245 2245 2240
				2221 2241 2251 2242 2251 2265 2251 2234 2228 2234 2242 2244 2238 2259 2262 2258 2242 2226
				2262 2238 2241 2244 2233 2241 2240 2237 2247 2244 2240 2237 2238 2242 2244 2244 2238 2259
				>;

			PS_Config_Lmt_LPWG_Rawdata_N = <
				964 955 959 960 961 957 958 958 (-65535) (-65535) 960 964 963 960 963 964 965 961
				961 963 960 957 955 962 958 961 963 964 960 961 961 960 962 961 963 960
				958 958 963 958 962 958 956 958 960 963 960 960 961 956 958 960 965 957
				960 954 961 962 954 959 958 958 955 956 959 960 957 956 959 957 961 957
				959 955 958 958 958 960 958 958 964 958 963 963 963 967 964 960 960 960
				960 961 959 960 961 960 960 958 962 955 960 958 957 962 961 960 958 958
				965 966 959 957 964 961 961 959 957 958 963 962 964 960 957 961 957 963
				964 955 963 961 956 957 957 957 960 963 967 966 964 964 956 953 955 962
				958 962 955 961 958 958 959 958 959 959 959 957 956 965 967 960 964 954
				960 962 963 964 964 961 964 966 961 964 960 959 960 955 954 960 957 959
				963 956 958 960 961 963 959 961 963 961 964 964 966 954 960 962 960 960
				961 963 960 963 958 958 957 961 960 959 957 956 957 964 962 958 960 960
				961 958 955 961 961 963 958 954 957 961 961 957 959 953 957 960 958 960
				961 957 959 960 960 958 957 960 964 963 961 961 961 954 961 962 963 958
				959 958 959 961 960 963 964 966 962 955 963 961 960 955 957 960 955 955
				961 962 958 963 957 958 959 967 961 963 963 963 963 961 958 962 960 950
				969 962 966 961 962 959 960 959 957 965 961 961 960 960 960 956 960 956
				961 957 960 960 963 964 960 963 964 958 963 961 962 959 952 963 958 967
				960 965 968 966 967 966 967 965 962 960 962 959 959 961 959 960 958 957
				958 965 955 964 953 955 954 959 961 958 962 966 963 961 962 962 961 958
				960 962 954 956 953 957 953 951 956 963 961 960 960 957 963 961 964 958
				961 961 963 961 962 960 961 965 961 955 959 958 961 960 964 960 960 958
				963 963 955 960 960 960 957 961 958 957 954 954 951 960 951 960 962 956
				960 965 962 961 963 963 961 969 960 964 961 958 960 957 959 960 964 962
				961 955 960 957 962 969 967 961 954 964 960 958 961 960 963 964 964 963
				960 961 960 959 963 963 963 963 957 963 958 957 957 954 954 952 966 964
				960 960 963 962 963 961 966 961 964 957 960 960 958 961 961 958 965 965
				960 960 957 960 963 964 965 963 957 959 960 957 955 964 961 960 956 959
				966 961 961 961 959 957 961 962 957 960 963 960 960 964 964 969 963 966
				963 965 961 963 965 960 965 968 965 958 964 963 961 962 963 962 962 960
				952 960 964 961 964 970 964 957 955 957 961 961 959 968 969 967 961 954
				969 959 960 961 957 960 960 958 963 961 960 958 959 961 961 961 959 968
				>;

			PS_Config_Lmt_LPWG_Diff_P = <
				60 60 60 60 60 60 60 60 65535 65535 60 60 60 60 60 60 60 60
				60 60 60 60 60 60 60 60 60 60 60 60 60 60 60 60 60 60
				60 60 60 60 60 60 60 60 60 60 60 60 60 60 60 60 60 60
				60 60 60 60 60 60 60 60 60 60 60 60 60 60 60 60 60 60
				60 60 60 60 60 60 60 60 60 60 60 60 60 60 60 60 60 60
				60 60 60 60 60 60 60 60 60 60 60 60 60 60 60 60 60 60
				60 60 60 60 60 60 60 60 60 60 60 60 60 60 60 60 60 60
				60 60 60 60 60 60 60 60 60 60 60 60 60 60 60 60 60 60
				60 60 60 60 60 60 60 60 60 60 60 60 60 60 60 60 60 60
				60 60 60 60 60 60 60 60 60 60 60 60 60 60 60 60 60 60
				60 60 60 60 60 60 60 60 60 60 60 60 60 60 60 60 60 60
				60 60 60 60 60 60 60 60 60 60 60 60 60 60 60 60 60 60
				60 60 60 60 60 60 60 60 60 60 60 60 60 60 60 60 60 60
				60 60 60 60 60 60 60 60 60 60 60 60 60 60 60 60 60 60
				60 60 60 60 60 60 60 60 60 60 60 60 60 60 60 60 60 60
				60 60 60 60 60 60 60 60 60 60 60 60 60 60 60 60 60 60
				60 60 60 60 60 60 60 60 60 60 60 60 60 60 60 60 60 60
				60 60 60 60 60 60 60 60 60 60 60 60 60 60 60 60 60 60
				60 60 60 60 60 60 60 60 60 60 60 60 60 60 60 60 60 60
				60 60 60 60 60 60 60 60 60 60 60 60 60 60 60 60 60 60
				60 60 60 60 60 60 60 60 60 60 60 60 60 60 60 60 60 60
				60 60 60 60 60 60 60 60 60 60 60 60 60 60 60 60 60 60
				60 60 60 60 60 60 60 60 60 60 60 60 60 60 60 60 60 60
				60 60 60 60 60 60 60 60 60 60 60 60 60 60 60 60 60 60
				60 60 60 60 60 60 60 60 60 60 60 60 60 60 60 60 60 60
				60 60 60 60 60 60 60 60 60 60 60 60 60 60 60 60 60 60
				60 60 60 60 60 60 60 60 60 60 60 60 60 60 60 60 60 60
				60 60 60 60 60 60 60 60 60 60 60 60 60 60 60 60 60 60
				60 60 60 60 60 60 60 60 60 60 60 60 60 60 60 60 60 60
				60 60 60 60 60 60 60 60 60 60 60 60 60 60 60 60 60 60
				60 60 60 60 60 60 60 60 60 60 60 60 60 60 60 60 60 60
				60 60 60 60 60 60 60 60 60 60 60 60 60 60 60 60 60 60
				>;

			PS_Config_Lmt_LPWG_Diff_N = <
				(-60) (-60) (-60) (-60) (-60) (-60) (-60) (-60) (-65535) (-65535) (-60) (-60) (-60) (-60) (-60) (-60) (-60) (-60)
				(-60) (-60) (-60) (-60) (-60) (-60) (-60) (-60) (-60) (-60) (-60) (-60) (-60) (-60) (-60) (-60) (-60) (-60)
				(-60) (-60) (-60) (-60) (-60) (-60) (-60) (-60) (-60) (-60) (-60) (-60) (-60) (-60) (-60) (-60) (-60) (-60)
				(-60) (-60) (-60) (-60) (-60) (-60) (-60) (-60) (-60) (-60) (-60) (-60) (-60) (-60) (-60) (-60) (-60) (-60)
				(-60) (-60) (-60) (-60) (-60) (-60) (-60) (-60) (-60) (-60) (-60) (-60) (-60) (-60) (-60) (-60) (-60) (-60)
				(-60) (-60) (-60) (-60) (-60) (-60) (-60) (-60) (-60) (-60) (-60) (-60) (-60) (-60) (-60) (-60) (-60) (-60)
				(-60) (-60) (-60) (-60) (-60) (-60) (-60) (-60) (-60) (-60) (-60) (-60) (-60) (-60) (-60) (-60) (-60) (-60)
				(-60) (-60) (-60) (-60) (-60) (-60) (-60) (-60) (-60) (-60) (-60) (-60) (-60) (-60) (-60) (-60) (-60) (-60)
				(-60) (-60) (-60) (-60) (-60) (-60) (-60) (-60) (-60) (-60) (-60) (-60) (-60) (-60) (-60) (-60) (-60) (-60)
				(-60) (-60) (-60) (-60) (-60) (-60) (-60) (-60) (-60) (-60) (-60) (-60) (-60) (-60) (-60) (-60) (-60) (-60)
				(-60) (-60) (-60) (-60) (-60) (-60) (-60) (-60) (-60) (-60) (-60) (-60) (-60) (-60) (-60) (-60) (-60) (-60)
				(-60) (-60) (-60) (-60) (-60) (-60) (-60) (-60) (-60) (-60) (-60) (-60) (-60) (-60) (-60) (-60) (-60) (-60)
				(-60) (-60) (-60) (-60) (-60) (-60) (-60) (-60) (-60) (-60) (-60) (-60) (-60) (-60) (-60) (-60) (-60) (-60)
				(-60) (-60) (-60) (-60) (-60) (-60) (-60) (-60) (-60) (-60) (-60) (-60) (-60) (-60) (-60) (-60) (-60) (-60)
				(-60) (-60) (-60) (-60) (-60) (-60) (-60) (-60) (-60) (-60) (-60) (-60) (-60) (-60) (-60) (-60) (-60) (-60)
				(-60) (-60) (-60) (-60) (-60) (-60) (-60) (-60) (-60) (-60) (-60) (-60) (-60) (-60) (-60) (-60) (-60) (-60)
				(-60) (-60) (-60) (-60) (-60) (-60) (-60) (-60) (-60) (-60) (-60) (-60) (-60) (-60) (-60) (-60) (-60) (-60)
				(-60) (-60) (-60) (-60) (-60) (-60) (-60) (-60) (-60) (-60) (-60) (-60) (-60) (-60) (-60) (-60) (-60) (-60)
				(-60) (-60) (-60) (-60) (-60) (-60) (-60) (-60) (-60) (-60) (-60) (-60) (-60) (-60) (-60) (-60) (-60) (-60)
				(-60) (-60) (-60) (-60) (-60) (-60) (-60) (-60) (-60) (-60) (-60) (-60) (-60) (-60) (-60) (-60) (-60) (-60)
				(-60) (-60) (-60) (-60) (-60) (-60) (-60) (-60) (-60) (-60) (-60) (-60) (-60) (-60) (-60) (-60) (-60) (-60)
				(-60) (-60) (-60) (-60) (-60) (-60) (-60) (-60) (-60) (-60) (-60) (-60) (-60) (-60) (-60) (-60) (-60) (-60)
				(-60) (-60) (-60) (-60) (-60) (-60) (-60) (-60) (-60) (-60) (-60) (-60) (-60) (-60) (-60) (-60) (-60) (-60)
				(-60) (-60) (-60) (-60) (-60) (-60) (-60) (-60) (-60) (-60) (-60) (-60) (-60) (-60) (-60) (-60) (-60) (-60)
				(-60) (-60) (-60) (-60) (-60) (-60) (-60) (-60) (-60) (-60) (-60) (-60) (-60) (-60) (-60) (-60) (-60) (-60)
				(-60) (-60) (-60) (-60) (-60) (-60) (-60) (-60) (-60) (-60) (-60) (-60) (-60) (-60) (-60) (-60) (-60) (-60)
				(-60) (-60) (-60) (-60) (-60) (-60) (-60) (-60) (-60) (-60) (-60) (-60) (-60) (-60) (-60) (-60) (-60) (-60)
				(-60) (-60) (-60) (-60) (-60) (-60) (-60) (-60) (-60) (-60) (-60) (-60) (-60) (-60) (-60) (-60) (-60) (-60)
				(-60) (-60) (-60) (-60) (-60) (-60) (-60) (-60) (-60) (-60) (-60) (-60) (-60) (-60) (-60) (-60) (-60) (-60)
				(-60) (-60) (-60) (-60) (-60) (-60) (-60) (-60) (-60) (-60) (-60) (-60) (-60) (-60) (-60) (-60) (-60) (-60)
				(-60) (-60) (-60) (-60) (-60) (-60) (-60) (-60) (-60) (-60) (-60) (-60) (-60) (-60) (-60) (-60) (-60) (-60)
				(-60) (-60) (-60) (-60) (-60) (-60) (-60) (-60) (-60) (-60) (-60) (-60) (-60) (-60) (-60) (-60) (-60) (-60)
				>;
		}; /* novatek-mp-criteria-hlt-b3 */
	};
};

/* TOUCH end */

/* accdet start */
&accdet {
	/* accdet micbias voltage: 0x07,2.7v;0x05,2.5v;0x02,1.9v */
	accdet-mic-vol = <6>;
	headset-mode-setting = <0x500 0x500 1 0x1f0 0x800 0x800 0x20 0x44>;
	accdet-plugout-debounce = <1>;
	/*1:ACC mode, 2:low cost without in bias, 6:low cost with in bias*/
	accdet-mic-mode = <1>;
	/* eint_level_trigger: 8,LEVEL_LOW(DEF) ;4,LV_HIGH;others,LV_LOW */
	headset-eint-level-pol = <8>;
	/*0--MD_MAX--UP_MAX--DW_MAX*/
	headset-three-key-threshold = <0 80 220 400>;
	headset-three-key-threshold-CDD = <0 121 192 600>;
	/*0--MD_MAX--VOICE_MAX--UP_MAX--DW_MAX*/
	headset-four-key-threshold = <0 58 121 192 400>;
	status = "okay";
};
/* accdet end */

&mt6370_pmu {
	mt6370,intr_gpio_num = <20>; /* direct defined GPIO num */
	mt6370,intr_gpio = <&pio 20 0x0>;
};
&mt6370_typec {
	mt6370pd,intr_gpio_num = <41>; /* direct defined GPIO num */
	mt6370pd,intr_gpio = <&pio 41 0x0>;
};

/* CONSYS GPIO standardization */
&pio {
	consys_pins_default: consys_default {
	};
	gpslna_pins_init: gpslna@0 {
		pins_cmd_dat {
			pinmux = <PINMUX_GPIO94__FUNC_GPIO94>;
			slew-rate = <0>;
			bias-disable;
			output-low;
		};
	};
	gpslna_pins_oh: gpslna@1 {
		pins_cmd_dat {
			pinmux = <PINMUX_GPIO94__FUNC_GPIO94>;
			slew-rate = <1>;
			output-high;
		};
	};
	gpslna_pins_ol: gpslna@2 {
		pins_cmd_dat {
			pinmux = <PINMUX_GPIO94__FUNC_GPIO94>;
			slew-rate = <1>;
			output-low;
		};
	};
};
&consys {
	pinctrl-names = "default", "gps_lna_state_init",
		"gps_lna_state_oh", "gps_lna_state_ol";
	pinctrl-0 = <&consys_pins_default>;
	pinctrl-1 = <&gpslna_pins_init>;
	pinctrl-2 = <&gpslna_pins_oh>;
	pinctrl-3 = <&gpslna_pins_ol>;
	status = "okay";
};
/* CONSYS end */

/* IRTX GPIO Start */
&irtx_pwm {
	pinctrl-names = "irtx_gpio_led_default", "irtx_gpio_led_set";
	pinctrl-0 = <&irtx_gpio_led_default>;
	pinctrl-1 = <&irtx_gpio_led_set>;
	status = "okay";
};
&pio {
	/* IRTX GPIO Settings -Start */
	/* default: GPIO0, output, high */
	irtx_gpio_led_default:irtx_gpio_led_def@gpio12 {
		pins_cmd_dat {
			pinmux = <PINMUX_GPIO12__FUNC_GPIO12>;
			slew-rate = <1>;
			bias-disable;
			output-low;
			input-schmitt-enable = <0>;
		};
	};

	irtx_gpio_led_set:irtx_gpio_led_set@gpio12 {
		pins_cmd_dat {
			pinmux = <PINMUX_GPIO12__FUNC_PWM0>;
			slew-rate = <1>;
			output-high;
		};
	};
}; /* IRTX GPIO Settings -End */

/* DISPSYS GPIO standardization */
&pio {
	mtkfb_pins_lcm_rst_out1_gpio: lcm_rst_out1_gpio {
		pins_cmd_dat {
			pinmux = <PINMUX_GPIO45__FUNC_GPIO45>;
			slew-rate = <1>;
			output-high;
		};
	};

	mtkfb_pins_lcm_rst_out0_gpio: lcm_rst_out0_gpio {
		pins_cmd_dat {
			pinmux = <PINMUX_GPIO45__FUNC_GPIO45>;
			slew-rate = <1>;
			output-low;
		};
	};

	mtkfb_pins_lcm_dsi_te: lcm_dsi_te {
		pins_cmd_dat {
			pinmux = <PINMUX_GPIO44__FUNC_DSI_TE>;
		};
	};
};

&mtkfb {
	pinctrl-names =
		"lcm_rst_out1_gpio", "lcm_rst_out0_gpio",
		"mode_te_te";
	pinctrl-0 = <&mtkfb_pins_lcm_rst_out1_gpio>;
	pinctrl-1 = <&mtkfb_pins_lcm_rst_out0_gpio>;
	pinctrl-2 = <&mtkfb_pins_lcm_dsi_te>;
	status = "okay";
};

/* DISPSYS GPIO standardization end*/

&bat_gm30 {
		io-channels = <&auxadc 2>;
		io-channel-names = "batteryID-channel";	
};
&pio {
		mtk_pins_usb_burn_en0: dischg_disable{
                pins_cmd_dat {
                        pinmux = <PINMUX_GPIO166__FUNC_GPIO166>;
                        slew-rate = <1>;
                        output-low;
                };
		};

		mtk_pins_usb_burn_en1: dischg_enable{
                pins_cmd_dat {
                        pinmux = <PINMUX_GPIO166__FUNC_GPIO166>;
                        slew-rate = <1>;
                        output-high;
                };
		};
};
#include <oppo6769_206AC/cust.dtsi>
#include "mediatek/cust_mt6768_camera.dtsi"
//#include "mediatek/cust_mt6768_touch_1080x2160.dtsi"
#include "mediatek/bq25910.dtsi"
#include "mediatek/bq2589x.dtsi"
/*End of this file, DO NOT ADD ANYTHING HERE*/
